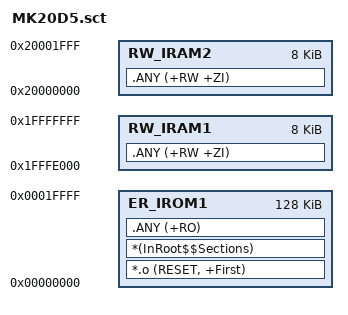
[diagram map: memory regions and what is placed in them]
LR_IROM1 0x00000000 0x00020000  {    ; load region size_region

  ER_IROM1 0x00000000 0x00020000  {  ; load address = execution address
   *.o (RESET, +First)
   *(InRoot$$Sections)
   .ANY (+RO)
  }
  
  RW_IRAM1 0x1FFFE000 0x00002000  {  ; RW data
   .ANY (+RW +ZI)
  }
  
  RW_IRAM2 0x20000000 0x00002000  {
   .ANY (+RW +ZI)
  }
}

